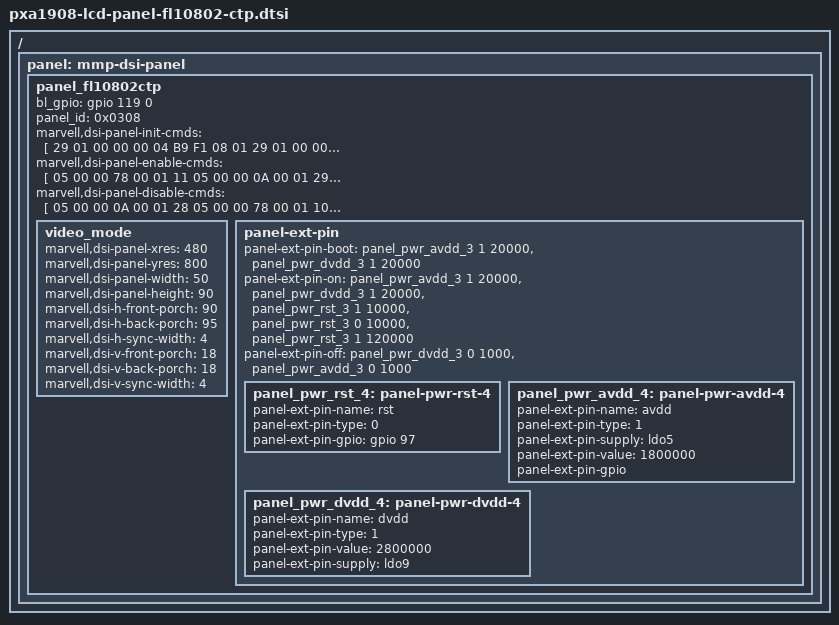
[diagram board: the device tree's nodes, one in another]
/*
 *  Copyright (C) 2014 Marvell Technology Group Ltd.
 *  Author: Hongyan Song <hysong@marvell.com>
 *
 *  This program is free software; you can redistribute it and/or modify
 *  it under the terms of the GNU General Public License version 2 as
 *  publishhed by the Free Software Foundation.
 */

/ {
	panel: mmp-dsi-panel {
		panel_fl10802ctp {
			/*
			 * BACKLIGHT CONTROL BY GPIO
			 */
			bl_gpio = <&gpio 119 0>;
			panel_id = <0x0308>;
			/*
			 * DSI PACKET HEADER INFO
			 * @ data type : 1byte
			 * @ command type : 1byte
			 * @ delay(msec) : 2byte
			 * @ size of data : 2byte
			 */
			marvell,dsi-panel-init-cmds = [
				29 01 00 00 00 04 B9 F1 08 01
				29 01 00 00 00 05 B1 26 1E 1E 87
				29 01 00 00 00 02 B2 23
				29 01 00 00 00 09 B3 00 00 06 06 20 20 30 30
				29 01 00 00 00 12 BA 31 00 44 25 91 0A 00 00 C1 00 00 00 0D 02 1D B9 EE
				29 01 00 00 00 06 E3 04 04 01 01 00
				29 01 00 00 00 02 B4 02
				29 01 00 00 00 03 B5 05 05
				29 01 00 00 00 03 B6 60 60
				29 01 00 00 00 03 B8 64 28
				29 01 00 00 00 02 CC 00
				29 01 00 00 00 02 BC 47
				29 01 00 00 00 34 E9 00 00 0F 03 36 0A 90 10 01
						  00 37 13 0A 90 37 00 00 18 00
						  00 00 25 09 80 40 00 24 60 00
						  00 00 09 81 50 01 35 70 00 00
						  00 00 00 00 00 00 00 00 00 00 00 00
				29 01 00 00 00 17 EA 94 00 00 00 08 95 10 07 35
						  10 00 00 00 08 94 00 06 24 00 00 00 00
				29 01 00 00 00 23 E0 00 00 08 0D 0F 29 28 35 09
						  11 10 13 17 14 15 13 19 00 00
						  18 0D 0F 29 28 35 09 11 10 13
						  17 14 15 13 19
			];
			marvell,dsi-panel-enable-cmds = [
				05 00 00 78 00 01	11
				05 00 00 0A 00 01	29
			];
			marvell,dsi-panel-disable-cmds = [
				05 00 00 0A 00 01	28
				05 00 00 78 00 01	10
			];
			video_mode {
				marvell,dsi-panel-xres = <480>;
				marvell,dsi-panel-yres = <800>;
				marvell,dsi-panel-width= <50>;      /* screen width in mm */
				marvell,dsi-panel-height = <90>;    /* screen height in mm */
				marvell,dsi-h-front-porch = <90>;   /* right margin */
				marvell,dsi-h-back-porch = <95>;    /* left margin */
				marvell,dsi-h-sync-width = <4>;    /* hsync len */
				marvell,dsi-v-front-porch = <18>;    /* lower margin */
				marvell,dsi-v-back-porch = <18>;    /* upper margin */
				marvell,dsi-v-sync-width = <4>;     /* vsync len */
			};
			panel-ext-pin {
				/*
				 * Three properties are required
				 * to control pwr pin
				 * @node : panel-ext-pin node
				 * @on : <0> - off / <1> - on
				 * @usec : delay time of usec
				 */
				/*
				 * panel-ext-pin-boot sequence
				 * is skip power on mode
				 */
				panel-ext-pin-boot = <
					&panel_pwr_avdd_3  1 20000
					&panel_pwr_dvdd_3  1 20000
				>;
				panel-ext-pin-on = <
					&panel_pwr_avdd_3  1 20000
					&panel_pwr_dvdd_3  1 20000
					&panel_pwr_rst_3   1 10000
					&panel_pwr_rst_3   0 10000
					&panel_pwr_rst_3   1 120000
				>;
				panel-ext-pin-off = <
					&panel_pwr_dvdd_3  0 1000
					&panel_pwr_avdd_3  0 1000
				>;
				/*
				 * There are four properties to define pwr pin
				 * <prefix>-name : pin name
				 * <prefix>-type : <0> - GPIO, <1> - PMIC Regulator
				 * <prefix>-gpio : If the type is GPIO, assign a gpio.
				 * <prefix>-supply : If the type is PMIC Regulator, assign a regulator.
				 */
				panel_pwr_rst_4: panel-pwr-rst-4 {
					panel-ext-pin-name = "rst";
					panel-ext-pin-type = <0>;
					panel-ext-pin-gpio = <&gpio 97 0>;
				};
				panel_pwr_avdd_4: panel-pwr-avdd-4 {
					panel-ext-pin-name = "avdd";
					panel-ext-pin-type = <1>;
					panel-ext-pin-supply = <&ldo5>;
					panel-ext-pin-value = <1800000>;
					panel-ext-pin-gpio;
				};
				panel_pwr_dvdd_4: panel-pwr-dvdd-4 {
					panel-ext-pin-name = "dvdd";
					panel-ext-pin-type = <1>;
					panel-ext-pin-value = <2800000>;
					panel-ext-pin-supply = <&ldo9>;
				};
			};
		};
	};
};
